# CY8C5868AXI_LP035 register map
File version: 0.1
CY8C58LP
Registers are 8-bit, read-write, no defined reset value unless marked. A register's access mark holds for its fields unless they carry their own. Offsets are from the block's base; lines under a group give offsets from that group; [hi:lo] are bit positions; {n}, {i} and the like mark numbered series; 'fields as' and 'values as' point back to an identical list; <NAME> marks a mode.

## Memory map
0x00000000 ADC_TURBIDO — SAR ADC
0x00000000 TimerPID
0x00000000 Turbido_PGA
0x00000000 ADC
0x00000000 pwmAgitator_1
0x00000000 UART — USBFS
0x00000000 Peltier1_PWM_Ctrl
0x00000000 Peltier2_PWM_Ctrl
0x00000000 pwmFan_1
0x00000000 pwmFan_2
0x00000000 CAN_1
0x00000000 pwmAgitator_2
0x40006472 Peltier_Enable
0x40006475 Peltier1_Ctrl
0x4000647C Peltier2_Ctrl

## ADC_TURBIDO — SAR ADC
Base 0x00000000
0x40004616 SAR_TR0 — SAR trim register
{0x40005908+i} SAR_CSR{i} (i=0..6) — SAR status and control register {i}
0x40005B28 SAR_SW0 — SAR Analog Routing Register 0
{0x40005B28+i} SAR_SW{i} (i=2..4) — SAR Analog Routing Register {i}
0x40005B2E SAR_SW6 — SAR Analog Routing Register 6
0x40005B2F SAR_CLK — SAR Clock Selection Register
0x40005BA2 SAR_WRK 16-bit — SAR working register

## Peltier_Enable
Base 0x40006472
0x00 Peltier_Enable_CONTROL_REG

## Peltier2_Ctrl
Base 0x4000647C
Registers as Peltier_Enable (with Peltier_Enable read as Peltier2_Ctrl).

## Peltier1_Ctrl
Base 0x40006475
Registers as Peltier_Enable (with Peltier_Enable read as Peltier1_Ctrl).

## TimerPID
Base 0x00000000
0x40006404 TimerPID_COUNTER 24-bit — UDB.A0 - Current Down Counter Value
0x40006424 TimerPID_PERIOD 24-bit — UDB.D0 - Assigned Period
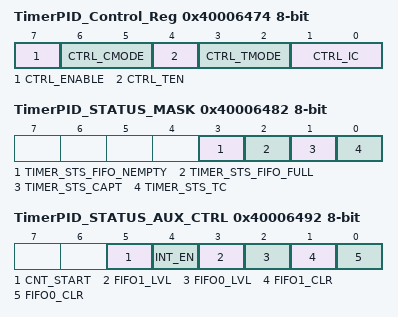
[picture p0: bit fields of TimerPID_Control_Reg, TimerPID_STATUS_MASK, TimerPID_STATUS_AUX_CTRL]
0x40006474 TimerPID_Control_Reg — UDB Control Register - Assigned Control Register Value
  [7] CTRL_ENABLE — Enable the Timer
  [6:5] CTRL_CMODE — Capture Mode
  [4] CTRL_TEN — Trigger Enable Bit
  [3:2] CTRL_TMODE — Trigger Mode
  [1:0] CTRL_IC — Interrupt Count
0x40006482 TimerPID_STATUS_MASK — UDB Status bits Interrupt Mask Enable Register
  [3] TIMER_STS_FIFO_NEMPTY ro — FIFO Empty status
  [2] TIMER_STS_FIFO_FULL ro — FIFO Full Status
  [1] TIMER_STS_CAPT ro — Enables the Interrupt on Capture
  [0] TIMER_STS_TC ro — Enables the Interrupt on TC
0x40006492 TimerPID_STATUS_AUX_CTRL — UDB Auxilliary Control Register
  [5] CNT_START — FIFO0 clear
    0=E_CNT_START0 (Disable counter); 1=E_CNT_START1 (Enable counter)
  [4] INT_EN
    0=E_INT_EN0 (Interrupt disabled); 1=E_INT_EN1 (Interrupt enabled)
  [3] FIFO1_LVL — FIFO level
    0=E_FIFO_LVL_0 (FIFO LVL: input mode: FIFO not full; output mode: FIFO not empty); 1=E_FIFO_LVL_1 (FIFO LVL: input mode: FIFO at least 1/2 empty; output mode: FIFO at least 1/2 full)
  [2] FIFO0_LVL — FIFO level
    values as FIFO1_LVL
  [1] FIFO1_CLR — FIFO1 clear
    0=E_FIFO_CLR_0 (Normal FIFO operation); 1=E_FIFO_CLR_1 (Clear FIFO state)
  [0] FIFO0_CLR — FIFO0 clear
    values as FIFO1_CLR

## pwmAgitator_1
Base 0x00000000
0x40006428 pwmAgitator_1_COMPARE_Reg 16-bit — UDB.D0 - Assigned Compare Value
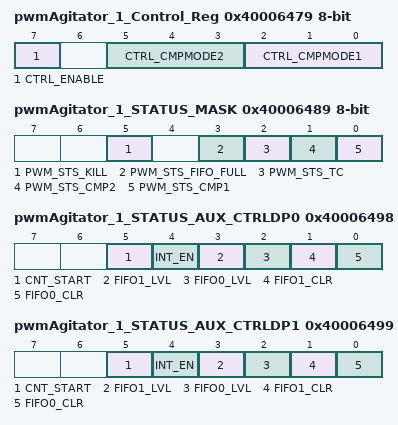
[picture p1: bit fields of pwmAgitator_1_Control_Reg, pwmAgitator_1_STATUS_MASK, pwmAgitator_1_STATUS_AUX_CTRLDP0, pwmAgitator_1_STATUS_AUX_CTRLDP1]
0x40006479 pwmAgitator_1_Control_Reg — UDB Control Register - Assigned Control Register Value
  [7] CTRL_ENABLE — Enable the PWM
  [5:3] CTRL_CMPMODE2 — Compare mode 2
  [2:0] CTRL_CMPMODE1 — Compare mode 1
0x40006489 pwmAgitator_1_STATUS_MASK — UDB Status bits Interrupt Mask Enable Register
  [5] PWM_STS_KILL ro — Enables the Interrupt on Kill
  [3] PWM_STS_FIFO_FULL ro — FIFO Full Status Mask
  [2] PWM_STS_TC ro — Enables the Interrupt on Terminal Count
  [1] PWM_STS_CMP2 ro — Enables the Interrupt on Compare 2
  [0] PWM_STS_CMP1 ro — Enables the Interrupt on Compare 1
0x40006498 pwmAgitator_1_STATUS_AUX_CTRLDP0 — UDB Auxilliary Control Register
  [5] CNT_START — FIFO0 clear
    0=E_CNT_START0 (Disable counter); 1=E_CNT_START1 (Enable counter)
  [4] INT_EN
    0=E_INT_EN0 (Interrupt disabled); 1=E_INT_EN1 (Interrupt enabled)
  [3] FIFO1_LVL — FIFO level
    0=E_FIFO_LVL_0 (FIFO LVL: input mode: FIFO not full; output mode: FIFO not empty); 1=E_FIFO_LVL_1 (FIFO LVL: input mode: FIFO at least 1/2 empty; output mode: FIFO at least 1/2 full)
  [2] FIFO0_LVL — FIFO level
    values as FIFO1_LVL
  [1] FIFO1_CLR — FIFO1 clear
    0=E_FIFO_CLR_0 (Normal FIFO operation); 1=E_FIFO_CLR_1 (Clear FIFO state)
  [0] FIFO0_CLR — FIFO0 clear
    values as FIFO1_CLR
0x40006499 pwmAgitator_1_STATUS_AUX_CTRLDP1 — UDB Auxilliary Control Register
  fields as pwmAgitator_1_STATUS_AUX_CTRLDP0
